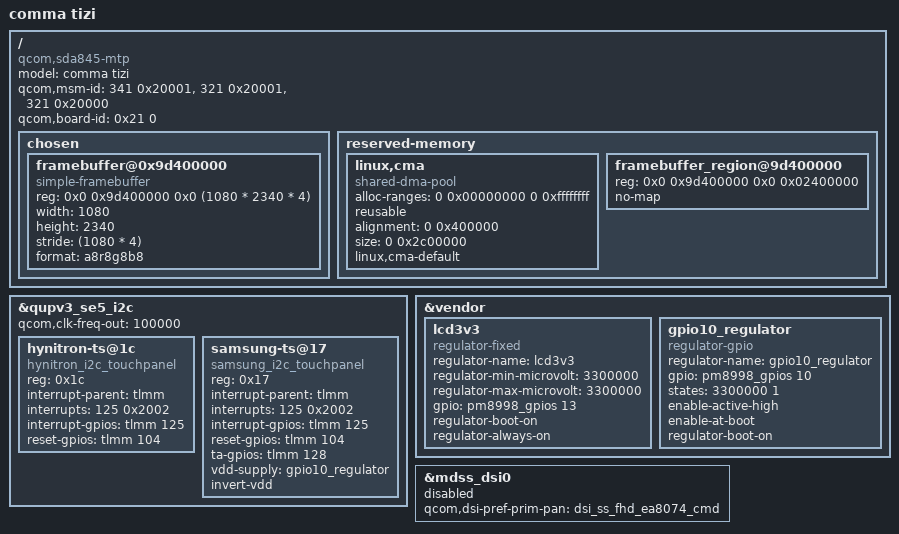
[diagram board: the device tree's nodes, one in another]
/* Copyright (c) 2017, The Linux Foundation. All rights reserved.
 *
 * This program is free software; you can redistribute it and/or modify
 * it under the terms of the GNU General Public License version 2 and
 * only version 2 as published by the Free Software Foundation.
 *
 * This program is distributed in the hope that it will be useful,
 * but WITHOUT ANY WARRANTY; without even the implied warranty of
 * MERCHANTABILITY or FITNESS FOR A PARTICULAR PURPOSE.  See the
 * GNU General Public License for more details.
 */


/dts-v1/;

#include <dt-bindings/clock/qcom,gcc-sdm845.h>
#include <dt-bindings/clock/qcom,camcc-sdm845.h>
#include <dt-bindings/clock/qcom,dispcc-sdm845.h>
#include <dt-bindings/clock/qcom,rpmh.h>
#include <dt-bindings/interrupt-controller/arm-gic.h>

#include "sda845-v2.1.dtsi"

#include "comma_common.dtsi"
#include "dsi-panel-mate10-lite-video.dtsi"

/* touch panel I2C, /dev/i2c-2 */
&qupv3_se5_i2c {
  status = "ok";
  qcom,clk-freq-out = <100000>;

  hynitron-ts@1c {
    compatible = "hynitron_i2c_touchpanel";
    reg = <0x1c>;
    interrupt-parent = <&tlmm>;
		interrupts = <125 0x2002>;
    interrupt-gpios = <&tlmm 125 0x2002>;
    reset-gpios = <&tlmm 104 0>;
  };

  samsung-ts@17 {
    compatible = "samsung_i2c_touchpanel";
    reg = <0x17>;
    interrupt-parent = <&tlmm>;
		interrupts = <125 0x2002>;
    interrupt-gpios = <&tlmm 125 0x2002>;
    reset-gpios = <&tlmm 104 0>;
    ta-gpios = <&tlmm 128 0>;
    vdd-supply = <&gpio10_regulator>;
    invert-vdd;
  };
};

&vendor {
	lcd3v3: lcd3v3 {
    status = "ok";

    compatible = "regulator-fixed";
    regulator-name = "lcd3v3";
    regulator-min-microvolt = <3300000>;
    regulator-max-microvolt = <3300000>;

    gpio = <&pm8998_gpios 13 0>;
    regulator-boot-on;
    regulator-always-on;
  };

	gpio10_regulator: gpio10_regulator {
		status = "ok";

		compatible = "regulator-gpio";
		regulator-name = "gpio10_regulator";

		gpio = <&pm8998_gpios 10 0>;
    states = <3300000 1>;
		enable-active-high;
    enable-at-boot;
		regulator-boot-on;
  };
};

&mdss_dsi0 {
	status = "disabled";
  qcom,dsi-pref-prim-pan = <&dsi_ss_fhd_ea8074_cmd>;
};

/* Board definition */
/ {
	model = "comma tizi";
	compatible = "qcom,sda845-mtp", "qcom,sda845", "qcom,mtp";
	qcom,msm-id = <341 0x20001>, <321 0x20001>, <321 0x20000>;
	qcom,board-id = <0x21 0>;



    chosen {
        #address-cells = <2>;
        #size-cells = <2>;
        ranges;
        
		framebuffer@0x9d400000 {
			compatible = "simple-framebuffer";
			reg = <0x0 0x9d400000 0x0 (1080 * 2340 * 4)>;
			width = <1080>;
			height = <2340>;
			stride = <(1080 * 4)>;
			format = "a8r8g8b8";
		};
    };
    
    reserved-memory {
        #address-cells = <2>;
        #size-cells = <2>;
        ranges;
        
		linux,cma {
			compatible = "shared-dma-pool";
			alloc-ranges = <0 0x00000000 0 0xffffffff>;
			reusable;
			alignment = <0 0x400000>;
			size = <0 0x2c00000>;
			linux,cma-default;
		};

		framebuffer_region@9d400000 {
			reg = <0x0 0x9d400000 0x0 0x02400000>;
			no-map;
		};
    };

};
